# PIC32CZ8110CA80144 device description
Architecture: CORTEX-M7; Family: PIC32C; Series: PIC32CZCA80
Registers are 32-bit, read-write, reset 0x0 unless marked. A register's access mark holds for its fields unless they carry their own. Offsets are from the block's base; [hi:lo] are bit positions; {n}, {i} and the like mark numbered series; 'fields as' and 'values as' point back to an identical list; <NAME> marks a mode.

## OSCCTRL — Oscillators Control
Instances: OSCCTRL 0x44040000
0x00 EVCTRL — Event Control
  [0] CFDEO — Clock Failure Detector Event Output Enable
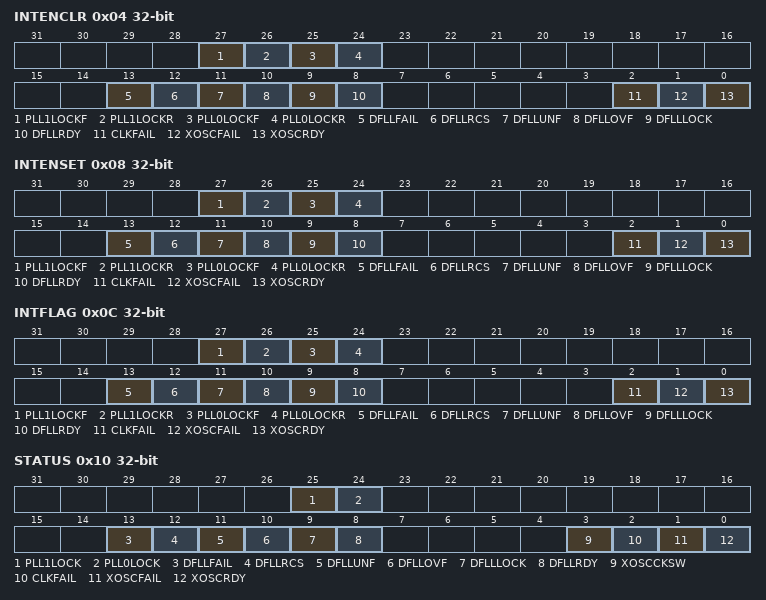
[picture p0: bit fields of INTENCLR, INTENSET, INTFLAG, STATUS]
0x04 INTENCLR (atomic clear) — Interrupt Enable Clear
  [27] PLL1LOCKF — PLL 1 Lock Fall Interrupt Enable
  [26] PLL1LOCKR — PLL 1 Lock Rise Interrupt Enable
  [25] PLL0LOCKF — PLL 0 Lock Fall Interrupt Enable
  [24] PLL0LOCKR — PLL 0 Lock Rise Interrupt Enable
  [13] DFLLFAIL — DFLL Startup Failure Interrupt Enable
  [12] DFLLRCS — DFLL Reference Clock Stopped Interrupt Enable
  [11] DFLLUNF — DFLL Tuner Underflow Interrupt Enable
  [10] DFLLOVF — DFLL Tuner Overflow Interrupt Enable
  [9] DFLLLOCK — DFLL Lock Interrupt Enable
  [8] DFLLRDY — DFLL Ready Interrupt Enable
  [2] CLKFAIL — XOSC Clock Failure Interrupt Enable
  [1] XOSCFAIL — XOSC Startup Failure Interrupt Enable
  [0] XOSCRDY — XOSC Ready Interrupt Enable
0x08 INTENSET (atomic set) — Interrupt Enable Set
  fields as INTENCLR
0x0C INTFLAG (atomic clear) — Interrupt Flag Status and Clear
  [27] PLL1LOCKF — PLL 1 Lock Fall
  [26] PLL1LOCKR — PLL 1 Lock Rise
  [25] PLL0LOCKF — PLL 0 Lock Fall
  [24] PLL0LOCKR — PLL 0 Lock Rise
  [13] DFLLFAIL — DFLL Startup Failure
  [12] DFLLRCS — DFLL Reference Clock Stopped
  [11] DFLLUNF — DFLL Tuner Underflow
  [10] DFLLOVF — DFLL Tuner Overflow
  [9] DFLLLOCK
  [8] DFLLRDY — DFLL Ready
  [2] CLKFAIL — XOSC Clock Failure
  [1] XOSCFAIL — XOSC Startup Failure
  [0] XOSCRDY — XOSC Ready
0x10 STATUS ro
  [25] PLL1LOCK
  [24] PLL0LOCK
  [13] DFLLFAIL — DFLL Startup Failure
  [12] DFLLRCS — DFLL Reference Clock Stopped
  [11] DFLLUNF — DFLL Tuner Underflow
  [10] DFLLOVF — DFLL Tuner Overflow
  [9] DFLLLOCK
  [8] DFLLRDY — DFLL Ready
  [3] XOSCCKSW — XOSC Clock Switch
  [2] CLKFAIL — XOSC Clock Failure
  [1] XOSCFAIL — XOSC Startup Failure
  [0] XOSCRDY — XOSC Ready
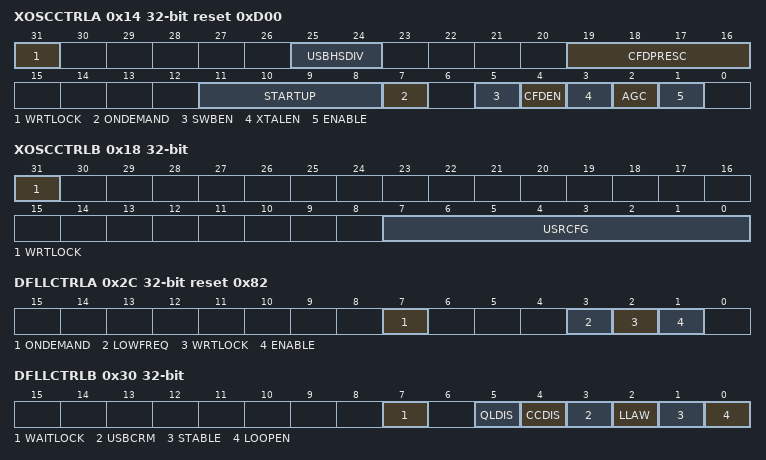
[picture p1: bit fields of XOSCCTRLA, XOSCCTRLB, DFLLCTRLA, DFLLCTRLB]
0x14 XOSCCTRLA reset 0xD00 — External Multipurpose Crystal Oscillator Control A
  [31] WRTLOCK — Write Lock for CTRLA register
  [25:24] USBHSDIV — USBHS Referrence Clock Division
    0=DIS (USBHS PLL reference XOSC clock is disabled); 1=DIV1 (USBHS PLL reference XOSC clock is divided by 1); 2=DIV2 (USBHS PLL reference XOSC clock is divided by 2); 3=DIV3 (USBHS PLL reference XOSC clock is divided by 4)
  [19:16] CFDPRESC — Clock Failure Detector Prescaler
    0=DIV1 (48 MHz); 1=DIV2 (24 MHz); 2=DIV4 (12 MHz); 3=DIV8 (6 MHz); 4=DIV16 (3 MHz); 5=DIV32 (1.5 MHz); 6=DIV64 (0.75 MHz); 7=DIV128 (0.3125 MHz)
  [11:8] STARTUP — Start-Up Time
    0=CYCLE1 (31 us); 1=CYCLE2 (61 us); 2=CYCLE4 (122 us); 3=CYCLE8 (244 us); 4=CYCLE16 (488 us); 5=CYCLE32 (977 us); 6=CYCLE64 (1953 us); 7=CYCLE128 (3906 us); 8=CYCLE256 (7813 us); 9=CYCLE512 (15625 us); 10=CYCLE1024 (31250 us); 11=CYCLE2048 (62500 us); 12=CYCLE4096 (125000 us); 13=CYCLE8192 (250000 us); 14=CYCLE16384 (500000 us); 15=CYCLE32768 (1000000 us)
  [7] ONDEMAND — On Demand Control
  [5] SWBEN — Xosc Clock Switch Back Enable
  [4] CFDEN — Clock Failure Detector Enable
  [3] XTALEN — Crystal Oscillator Enable
  [2] AGC — Auto Gain Control Loop Enable
  [1] ENABLE — Oscillator Enable
0x18 XOSCCTRLB — External Multipurpose Crystal Oscillator Control B
  [31] WRTLOCK — Write Lock for CTRLB register
  [7:0] USRCFG — User Configuration Control Bits
0x2C DFLLCTRLA reset 0x82 — DFLL48M Control A
  [7] ONDEMAND — On Demand Control
  [3] LOWFREQ — Low Frequency Mode
  [2] WRTLOCK — Write Lock
  [1] ENABLE — DFLL Enable
0x30 DFLLCTRLB (WSYNC) — DFLL48M Control B
  [7] WAITLOCK
  [5] QLDIS — Quick Lock Disable
  [4] CCDIS — Chill Cycle Disable
  [3] USBCRM — USB Clock Recovery Mode
  [2] LLAW — Lose Lock After Wake
  [1] STABLE — Stable DFLL Frequency
  [0] LOOPEN — Operating Mode Selection
0x34 DFLLTUNE (RWSYNC) — DFLL48M Tune
  [6:0] TUNE — Tune Value
0x38 DFLLDIFF ro (RSYNC) — DFLL48M Diff
  [15:0] DIFF — Multiplication Ratio Difference
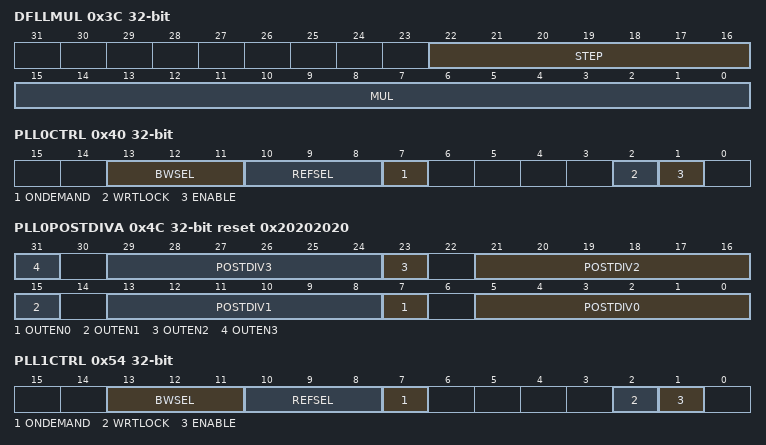
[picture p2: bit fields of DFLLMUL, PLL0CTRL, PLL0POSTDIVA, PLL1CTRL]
0x3C DFLLMUL (WSYNC) — DFLL48M Multiplier
  [22:16] STEP — Tune Maximum Step
  [15:0] MUL — DFLL Multiply Factor
0x40 PLL0CTRL — PLL Control
  [13:11] BWSEL — Bandwidth selection
  [10:8] REFSEL — Reference selection
    0=GCLK (Dedicated GCLK clock reference); 1=XOSC (XOSC clock reference); 2=DFLL48M (DFLL48M clock reference)
  [7] ONDEMAND — On Demand Control
  [2] WRTLOCK — Write Lock
  [1] ENABLE — PLL Enable
0x44 PLL0FBDIV — PLL Feed-Back Divider
  [9:0] FBDIV — PLL Feed-Back Divider Factor
0x48 PLL0REFDIV — PLL reference divider
  [5:0] REFDIV — PLL reference division factor
0x4C PLL0POSTDIVA reset 0x20202020 — PLL output clock divider A
  [8n+7] OUTEN{n} (n=0..3) — PLL output 0 enable
  [8n+5:8n] POSTDIV{n} (n=0..3) — PLL output 0 clock division factor
0x54 PLL1CTRL — PLL Control
  fields as PLL0CTRL
0x58 PLL1FBDIV — PLL Feed-Back Divider
  [9:0] FBDIV — PLL Feed-Back Divider Factor
0x5C PLL1REFDIV — PLL reference divider
  [5:0] REFDIV — PLL reference division factor
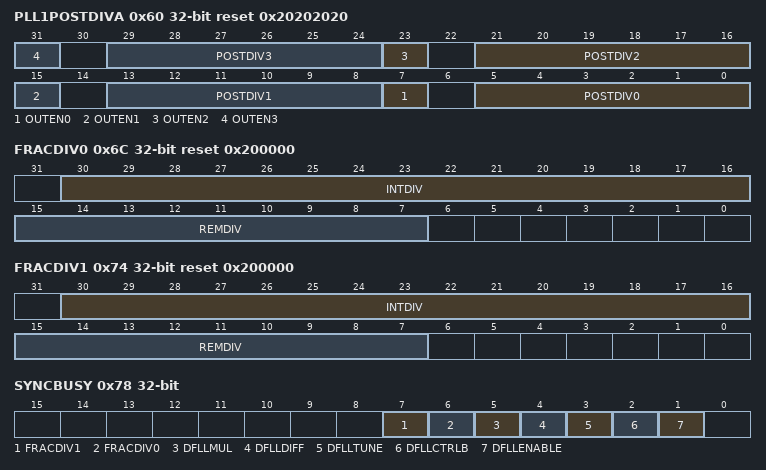
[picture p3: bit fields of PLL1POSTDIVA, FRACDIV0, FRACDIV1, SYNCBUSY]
0x60 PLL1POSTDIVA reset 0x20202020 — PLL output clock divider A
  fields as PLL0POSTDIVA
0x6C FRACDIV0 reset 0x200000 (WSYNC) — Fractional Divider
  [30:16] INTDIV — Frequency division factor integer part
  [15:7] REMDIV — Frequency division factor reminder part
0x74 FRACDIV1 reset 0x200000 (WSYNC) — Fractional Divider
  fields as FRACDIV0
0x78 SYNCBUSY ro — Synchronization Busy
  [7] FRACDIV1 — FRACDIV1 Synchronization Busy
  [6] FRACDIV0 — FRACDIV0 Synchronization Busy
  [5] DFLLMUL — DFLLMUL Synchronization Busy
  [4] DFLLDIFF — DFLLDIFF Synchronization Busy
  [3] DFLLTUNE — DFLLTUNE Synchronization Busy
  [2] DFLLCTRLB — DFLLCTRLB Synchronization Busy
  [1] DFLLENABLE — DFLL48M ENABLE Synchronization Busy
0x80 XOSCCAL — XOSC Calibration Register
  [15:0] CAL <DEFAULT> — XOSC Calibration
  [15:10] SPARES <FUSES_OSC_XTAL_HF_AGC_V2> — Spare bits
  [9] REDOSC <FUSES_OSC_XTAL_HF_AGC_V2> — reduce oscillation debug counter
  [8] REDGAIN <FUSES_OSC_XTAL_HF_AGC_V2> — reduce gain control timer
  [7] FLIPPOL <FUSES_OSC_XTAL_HF_AGC_V2> — flip output clock polarity
  [6] CMSEL <FUSES_OSC_XTAL_HF_AGC_V2> — clock buffer common mode selection
  [5] HYST <FUSES_OSC_XTAL_HF_AGC_V2> — loop hysteresis control
  [4:3] ENVAMP <FUSES_OSC_XTAL_HF_AGC_V2> — envelope amplitude at osci
  [2] KICKEREN <FUSES_OSC_XTAL_HF_AGC_V2> — Kicker enable
  [1:0] FTRANS <FUSES_OSC_XTAL_HF_AGC_V2> — Fine Transconductance programmability for Oscillator
0x88 RC48MCAL0 — RC48M Calibration 0
  [31:0] CAL <DEFAULT> — RC48M Calibration
  [22:20] cmp_pwr_ctrl <FUSES_OSC_RC48MHZ_V1> — Comparator power control
  [19] cmp_8m_lp <FUSES_OSC_RC48MHZ_V1> — Comparator 8MHz low-power
  [18] ldo_vout_boost <FUSES_OSC_RC48MHZ_V1>
  [17] out_buf_sel <FUSES_OSC_RC48MHZ_V1> — Output buffer select
  [16] iosc_boost <FUSES_OSC_RC48MHZ_V1>
  [13:6] proc_trim_mv <FUSES_OSC_RC48MHZ_V1> — Proc trim value
  [5:0] temp_trim_mv <FUSES_OSC_RC48MHZ_V1> — Temp trim value

## Notices in the file
Copyright (c) 2021 Microchip Technology Inc.
SPDX-License-Identifier: Apache-2.0
Licensed under the Apache License, Version 2.0 (the "License");
you may not use this file except in compliance with the License.
You may obtain a copy of the License at
http://www.apache.org/licenses/LICENSE-2.0
Unless required by applicable law or agreed to in writing, software
distributed under the License is distributed on an "AS IS" BASIS,
WITHOUT WARRANTIES OR CONDITIONS OF ANY KIND, either express or implied.
See the License for the specific language governing permissions and
limitations under the License.
